AUTOSAR XML (schema 3.1.2)
package /Components/SWC_ExMGslT1
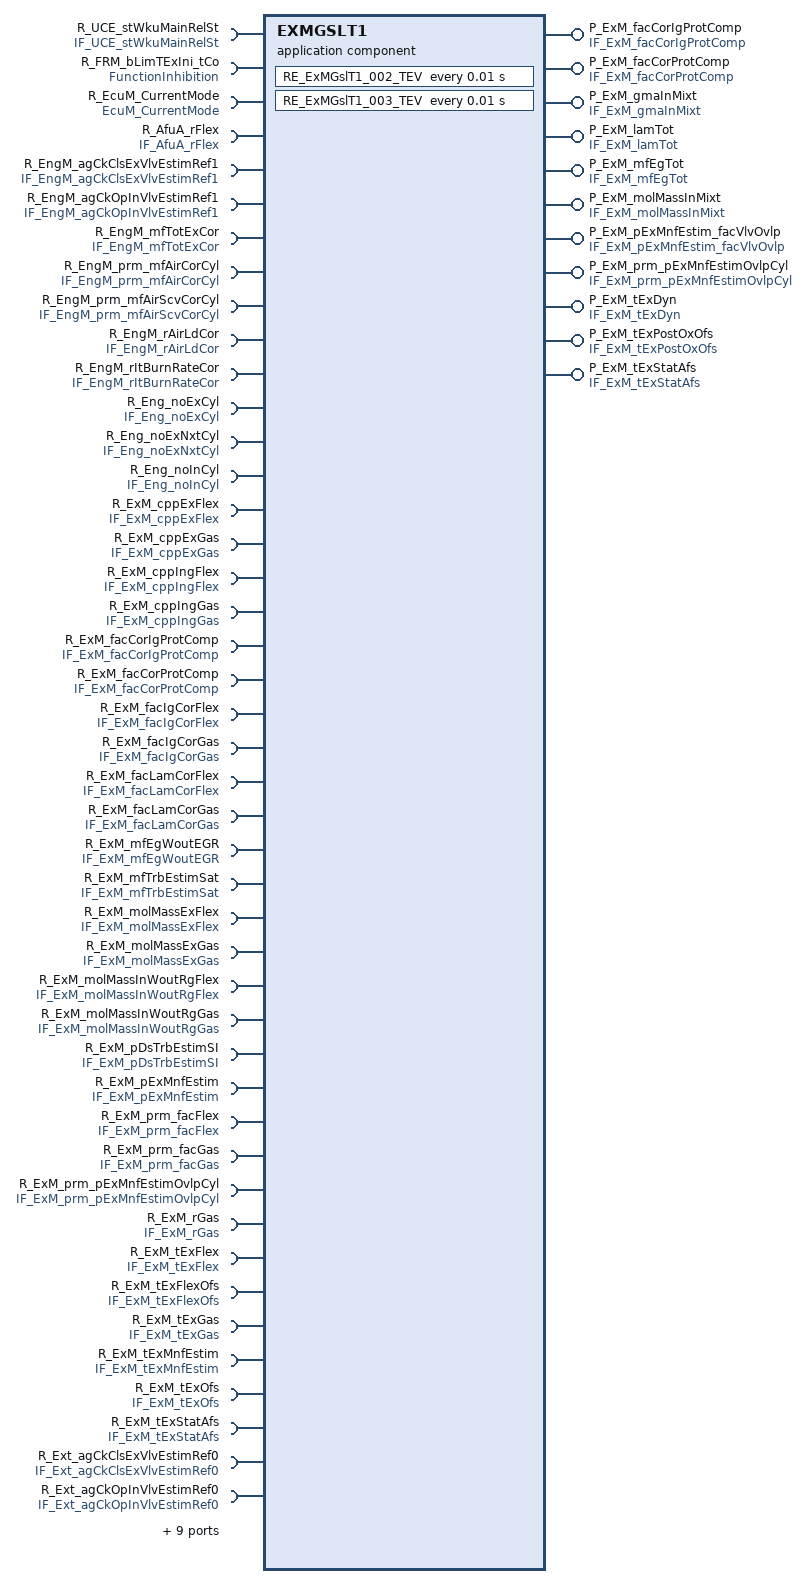
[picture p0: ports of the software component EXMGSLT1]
  application software component type EXMGSLT1  # ExMGslT1
    require port R_UCE_stWkuMainRelSt: required-interface=IF_UCE_stWkuMainRelSt
    require port R_FRM_bLimTExIni_tCo: required-interface=FunctionInhibition
    11 x provide port:
      P_ExM_facCorIgProtComp: unqueued-sender-com-spec{data-element=ExM_facCorIgProtComp, can-invalidate=false, init-value=UInt16InitValue}, provided-interface=IF_ExM_facCorIgProtComp
      P_ExM_facCorProtComp: unqueued-sender-com-spec{data-element=ExM_facCorProtComp, can-invalidate=false, init-value=UInt16InitValue1}, provided-interface=IF_ExM_facCorProtComp
      P_ExM_gmaInMixt: unqueued-sender-com-spec{data-element=ExM_gmaInMixt, can-invalidate=false, init-value=ConstantValue}, provided-interface=IF_ExM_gmaInMixt
      P_ExM_lamTot: unqueued-sender-com-spec{data-element=ExM_lamTot, can-invalidate=false, init-value=UInt32InitValue}, provided-interface=IF_ExM_lamTot
      P_ExM_mfEgTot: unqueued-sender-com-spec{data-element=ExM_mfEgTot, can-invalidate=false, init-value=UInt16InitValue3}, provided-interface=IF_ExM_mfEgTot
      P_ExM_molMassInMixt: unqueued-sender-com-spec{data-element=ExM_molMassInMixt, can-invalidate=false, init-value=ConstantValue5}, provided-interface=IF_ExM_molMassInMixt
      P_ExM_pExMnfEstim_facVlvOvlp: unqueued-sender-com-spec{data-element=ExM_pExMnfEstim_facVlvOvlp, can-invalidate=false, init-value=ConstantValue7}, provided-interface=IF_ExM_pExMnfEstim_facVlvOvlp
      P_ExM_prm_pExMnfEstimOvlpCyl: unqueued-sender-com-spec{data-element=ExM_prm_pExMnfEstimOvlpCyl, can-invalidate=false, init-value=ArrayConstantValue}, provided-interface=IF_ExM_prm_pExMnfEstimOvlpCyl
      P_ExM_tExDyn: unqueued-sender-com-spec{data-element=ExM_tExDyn, can-invalidate=false, init-value=ConstantValue9}, provided-interface=IF_ExM_tExDyn
      P_ExM_tExPostOxOfs: unqueued-sender-com-spec{data-element=ExM_tExPostOxOfs, can-invalidate=false, init-value=UInt16InitValue11}, provided-interface=IF_ExM_tExPostOxOfs
      P_ExM_tExStatAfs: unqueued-sender-com-spec{data-element=ExM_tExStatAfs, can-invalidate=false, init-value=UInt16InitValue13}, provided-interface=IF_ExM_tExStatAfs
    51 x require port:
      R_EcuM_CurrentMode: required-interface=EcuM_CurrentMode
      R_AfuA_rFlex: unqueued-receiver-com-spec{data-element=AfuA_rFlex, init-value=UInt8InitValue, resync-time=0}, required-interface=IF_AfuA_rFlex
      R_EngM_agCkClsExVlvEstimRef1: unqueued-receiver-com-spec{data-element=EngM_agCkClsExVlvEstimRef1, init-value=ConstantValue15, resync-time=0}, required-interface=IF_EngM_agCkClsExVlvEstimRef1
      R_EngM_agCkOpInVlvEstimRef1: unqueued-receiver-com-spec{data-element=EngM_agCkOpInVlvEstimRef1, init-value=ConstantValue17, resync-time=0}, required-interface=IF_EngM_agCkOpInVlvEstimRef1
      R_EngM_mfTotExCor: unqueued-receiver-com-spec{data-element=EngM_mfTotExCor, init-value=ConstantValue19, resync-time=0}, required-interface=IF_EngM_mfTotExCor
      R_EngM_prm_mfAirCorCyl: unqueued-receiver-com-spec{data-element=EngM_prm_mfAirCorCyl, init-value=ArrayConstantValue21, resync-time=0}, required-interface=IF_EngM_prm_mfAirCorCyl
      R_EngM_prm_mfAirScvCorCyl: unqueued-receiver-com-spec{data-element=EngM_prm_mfAirScvCorCyl, init-value=ArrayConstantValue23, resync-time=0}, required-interface=IF_EngM_prm_mfAirScvCorCyl
      R_EngM_rAirLdCor: unqueued-receiver-com-spec{data-element=EngM_rAirLdCor, init-value=ConstantValue25, resync-time=0}, required-interface=IF_EngM_rAirLdCor
      R_EngM_rItBurnRateCor: unqueued-receiver-com-spec{data-element=EngM_rItBurnRateCor, init-value=ConstantValue27, resync-time=0}, required-interface=IF_EngM_rItBurnRateCor
      R_Eng_noExCyl: unqueued-receiver-com-spec{data-element=Eng_noExCyl, init-value=ConstantValue29, resync-time=0}, required-interface=IF_Eng_noExCyl
      R_Eng_noExNxtCyl: unqueued-receiver-com-spec{data-element=Eng_noExNxtCyl, init-value=ConstantValue31, resync-time=0}, required-interface=IF_Eng_noExNxtCyl
      R_Eng_noInCyl: unqueued-receiver-com-spec{data-element=Eng_noInCyl, init-value=ConstantValue33, resync-time=0}, required-interface=IF_Eng_noInCyl
      R_ExM_cppExFlex: unqueued-receiver-com-spec{data-element=ExM_cppExFlex, init-value=UInt16InitValue35, resync-time=0}, required-interface=IF_ExM_cppExFlex
      R_ExM_cppExGas: unqueued-receiver-com-spec{data-element=ExM_cppExGas, init-value=SInt16InitValue, resync-time=0}, required-interface=IF_ExM_cppExGas
      R_ExM_cppIngFlex: unqueued-receiver-com-spec{data-element=ExM_cppIngFlex, init-value=ConstantValue1, resync-time=0}, required-interface=IF_ExM_cppIngFlex
      R_ExM_cppIngGas: unqueued-receiver-com-spec{data-element=ExM_cppIngGas, init-value=SInt16InitValue39, resync-time=0}, required-interface=IF_ExM_cppIngGas
      R_ExM_facCorIgProtComp: unqueued-receiver-com-spec{data-element=ExM_facCorIgProtComp, init-value=UInt16InitValue, resync-time=0}, required-interface=IF_ExM_facCorIgProtComp
      R_ExM_facCorProtComp: unqueued-receiver-com-spec{data-element=ExM_facCorProtComp, init-value=UInt16InitValue41, resync-time=0}, required-interface=IF_ExM_facCorProtComp
      R_ExM_facIgCorFlex: unqueued-receiver-com-spec{data-element=ExM_facIgCorFlex, init-value=UInt16InitValue43, resync-time=0}, required-interface=IF_ExM_facIgCorFlex
      R_ExM_facIgCorGas: unqueued-receiver-com-spec{data-element=ExM_facIgCorGas, init-value=UInt16InitValue45, resync-time=0}, required-interface=IF_ExM_facIgCorGas
      R_ExM_facLamCorFlex: unqueued-receiver-com-spec{data-element=ExM_facLamCorFlex, init-value=UInt16InitValue47, resync-time=0}, required-interface=IF_ExM_facLamCorFlex
      R_ExM_facLamCorGas: unqueued-receiver-com-spec{data-element=ExM_facLamCorGas, init-value=UInt16InitValue49, resync-time=0}, required-interface=IF_ExM_facLamCorGas
      R_ExM_mfEgWoutEGR: unqueued-receiver-com-spec{data-element=ExM_mfEgWoutEGR, init-value=UInt16InitValue51, resync-time=0}, required-interface=IF_ExM_mfEgWoutEGR
      R_ExM_mfTrbEstimSat: unqueued-receiver-com-spec{data-element=ExM_mfTrbEstimSat, init-value=UInt16InitValue53, resync-time=0}, required-interface=IF_ExM_mfTrbEstimSat
      R_ExM_molMassExFlex: unqueued-receiver-com-spec{data-element=ExM_molMassExFlex, init-value=UInt16InitValue55, resync-time=0}, required-interface=IF_ExM_molMassExFlex
      R_ExM_molMassExGas: unqueued-receiver-com-spec{data-element=ExM_molMassExGas, init-value=SInt32InitValue, resync-time=0}, required-interface=IF_ExM_molMassExGas
      R_ExM_molMassInWoutRgFlex: unqueued-receiver-com-spec{data-element=ExM_molMassInWoutRgFlex, init-value=UInt16InitValue57, resync-time=0}, required-interface=IF_ExM_molMassInWoutRgFlex
      R_ExM_molMassInWoutRgGas: unqueued-receiver-com-spec{data-element=ExM_molMassInWoutRgGas, init-value=SInt32InitValue59, resync-time=0}, required-interface=IF_ExM_molMassInWoutRgGas
      R_ExM_pDsTrbEstimSI: unqueued-receiver-com-spec{data-element=ExM_pDsTrbEstimSI, init-value=UInt16InitValue61, resync-time=0}, required-interface=IF_ExM_pDsTrbEstimSI
      R_ExM_pExMnfEstim: unqueued-receiver-com-spec{data-element=ExM_pExMnfEstim, init-value=UInt16InitValue63, resync-time=0}, required-interface=IF_ExM_pExMnfEstim
      R_ExM_prm_facFlex: unqueued-receiver-com-spec{data-element=ExM_prm_facFlex, init-value=rt_Array_UInt16_5InitValue, resync-time=0}, required-interface=IF_ExM_prm_facFlex
      R_ExM_prm_facGas: unqueued-receiver-com-spec{data-element=ExM_prm_facGas, init-value=rt_Array_UInt16_5InitValue65, resync-time=0}, required-interface=IF_ExM_prm_facGas
      R_ExM_prm_pExMnfEstimOvlpCyl: unqueued-receiver-com-spec{data-element=ExM_prm_pExMnfEstimOvlpCyl, init-value=ArrayConstantValue, resync-time=0}, required-interface=IF_ExM_prm_pExMnfEstimOvlpCyl
      R_ExM_rGas: unqueued-receiver-com-spec{data-element=ExM_rGas, init-value=UInt8InitValue67, resync-time=0}, required-interface=IF_ExM_rGas
      R_ExM_tExFlex: unqueued-receiver-com-spec{data-element=ExM_tExFlex, init-value=UInt16InitValue69, resync-time=0}, required-interface=IF_ExM_tExFlex
      R_ExM_tExFlexOfs: unqueued-receiver-com-spec{data-element=ExM_tExFlexOfs, init-value=SInt16InitValue71, resync-time=0}, required-interface=IF_ExM_tExFlexOfs
      R_ExM_tExGas: unqueued-receiver-com-spec{data-element=ExM_tExGas, init-value=SInt32InitValue73, resync-time=0}, required-interface=IF_ExM_tExGas
      R_ExM_tExMnfEstim: unqueued-receiver-com-spec{data-element=ExM_tExMnfEstim, init-value=ConstantValue75, resync-time=0}, required-interface=IF_ExM_tExMnfEstim
      R_ExM_tExOfs: unqueued-receiver-com-spec{data-element=ExM_tExOfs, init-value=SInt16InitValue77, resync-time=0}, required-interface=IF_ExM_tExOfs
      R_ExM_tExStatAfs: unqueued-receiver-com-spec{data-element=ExM_tExStatAfs, init-value=UInt16InitValue79, resync-time=0}, required-interface=IF_ExM_tExStatAfs
      R_Ext_agCkClsExVlvEstimRef0: unqueued-receiver-com-spec{data-element=Ext_agCkClsExVlvEstimRef0, init-value=ConstantValue81, resync-time=0}, required-interface=IF_Ext_agCkClsExVlvEstimRef0
      R_Ext_agCkOpInVlvEstimRef0: unqueued-receiver-com-spec{data-element=Ext_agCkOpInVlvEstimRef0, init-value=ConstantValue83, resync-time=0}, required-interface=IF_Ext_agCkOpInVlvEstimRef0
      R_Ext_nEng: unqueued-receiver-com-spec{data-element=Ext_nEng, init-value=ConstantValue85, resync-time=0}, required-interface=IF_Ext_nEng
      R_Ext_tCoMes: unqueued-receiver-com-spec{data-element=Ext_tCoMes, init-value=ConstantValue87, resync-time=0}, required-interface=IF_Ext_tCoMes
      R_FARSp_rMixtCylSp: unqueued-receiver-com-spec{data-element=FARSp_rMixtCylSp, init-value=ConstantValue89, resync-time=0}, required-interface=IF_FARSp_rMixtCylSp
      R_IgSys_bAcvStructAir: unqueued-receiver-com-spec{data-element=IgSys_bAcvStructAir, init-value=ConstantValue91, resync-time=0}, required-interface=IF_IgSys_bAcvStructAir
      R_IgSys_lamClc: unqueued-receiver-com-spec{data-element=IgSys_lamClc, init-value=ConstantValue93, resync-time=0}, required-interface=IF_IgSys_lamClc
      R_IgSys_rDynIgSpEfc: unqueued-receiver-com-spec{data-element=IgSys_rDynIgSpEfc, init-value=ConstantValue95, resync-time=0}, required-interface=IF_IgSys_rDynIgSpEfc
      R_InThM_tAirUsInVlvEstim: unqueued-receiver-com-spec{data-element=InThM_tAirUsInVlvEstim, init-value=ConstantValue97, resync-time=0}, required-interface=IF_InThM_tAirUsInVlvEstim
      R_InjSys_bTotCutOff: unqueued-receiver-com-spec{data-element=InjSys_bTotCutOff, init-value=ConstantValue99, resync-time=0}, required-interface=IF_InjSys_bTotCutOff
      R_UsThrM_pAirExt: unqueued-receiver-com-spec{data-element=UsThrM_pAirExt, init-value=ConstantValue101, resync-time=0}, required-interface=IF_UsThrM_pAirExt
  59 x constant specification:
    ArrayConstantValue
      value:
        array specification ArrayConstantValue: type=rt_Array_UInt16_6_m2
          6 x integer literal, all with type=DT_ExM_prm_pExMnfEstimOvlpCyl, value=0:
            Const
            Const{1..5}
    ArrayConstantValue21
      value:
        array specification ArrayConstantValue21: type=rt_Array_UInt16_6_m6
          6 x integer literal, all with type=DT_EngM_prm_mfAirCorCyl, value=43:
            Const
            Const{1..5}
    ArrayConstantValue23
      value:
        array specification ArrayConstantValue23: type=rt_Array_UInt16_6_m7
          6 x integer literal, all with type=DT_EngM_prm_mfAirScvCorCyl, value=0:
            Const
            Const{1..5}
    ConstantValue
      value:
        integer literal ConstantValue: type=DT_ExM_gmaInMixt, value=0
    ConstantValue1
      value:
        integer literal ConstantValue1: type=DT_ExM_cppIngFlex, value=2000
    ConstantValue101
      value:
        integer literal ConstantValue101: type=DT_UsThrM_pAirExt, value=0
    ConstantValue15
      value:
        integer literal ConstantValue15: type=DT_EngM_agCkClsExVlvEstimRef1, value=0
    ConstantValue17
      value:
        integer literal ConstantValue17: type=DT_EngM_agCkOpInVlvEstimRef1, value=0
    ConstantValue19
      value:
        integer literal ConstantValue19: type=DT_EngM_mfTotExCor, value=0
    ConstantValue25
      value:
        integer literal ConstantValue25: type=DT_EngM_rAirLdCor, value=0
    ConstantValue27
      value:
        integer literal ConstantValue27: type=DT_EngM_rItBurnRateCor, value=0
    ConstantValue29
      value:
        integer literal ConstantValue29: type=DT_Eng_noExCyl, value=1
    ConstantValue31
      value:
        integer literal ConstantValue31: type=DT_Eng_noExNxtCyl, value=1
    ConstantValue33
      value:
        integer literal ConstantValue33: type=DT_Eng_noInCyl, value=1
    ConstantValue5
      value:
        integer literal ConstantValue5: type=DT_ExM_molMassInMixt, value=0
    ConstantValue7
      value:
        integer literal ConstantValue7: type=DT_ExM_pExMnfEstim_facVlvOvlp, value=0
    ConstantValue75
      value:
        integer literal ConstantValue75: type=DT_ExM_tExMnfEstim, value=4800
    ConstantValue81
      value:
        integer literal ConstantValue81: type=DT_Ext_agCkClsExVlvEstimRef0, value=-1024
    ConstantValue83
      value:
        integer literal ConstantValue83: type=DT_Ext_agCkOpInVlvEstimRef0, value=-1024
    ConstantValue85
      value:
        integer literal ConstantValue85: type=DT_Ext_nEng, value=0
    ConstantValue87
      value:
        integer literal ConstantValue87: type=DT_Ext_tCoMes, value=20
    ConstantValue89
      value:
        integer literal ConstantValue89: type=DT_FARSp_rMixtCylSp, value=4096
    ConstantValue9
      value:
        integer literal ConstantValue9: type=DT_ExM_tExDyn, value=0
    ConstantValue91
      value:
        boolean literal ConstantValue91: type=DT_IgSys_bAcvStructAir, value=false
    ConstantValue93
      value:
        integer literal ConstantValue93: type=DT_IgSys_lamClc, value=0
    ConstantValue95
      value:
        integer literal ConstantValue95: type=DT_IgSys_rDynIgSpEfc, value=0
    ConstantValue97
      value:
        integer literal ConstantValue97: type=DT_InThM_tAirUsInVlvEstim, value=0
    ConstantValue99
      value:
        boolean literal ConstantValue99: type=DT_InjSys_bTotCutOff, value=false
    rt_Array_UInt16_5InitValue
      value:
        array specification rt_Array_UInt16_5InitValue: type=rt_Array_UInt16_5_m0
          5 x integer literal, all with type=DT_ExM_prm_facFlex, value=0:
            UInt16_{1..5}
    rt_Array_UInt16_5InitValue65
      value:
        array specification rt_Array_UInt16_5InitValue65: type=Array_5_UInt16
          5 x integer literal, all with type=DT_ExM_prm_facGas, value=0:
            UInt16_{1..5}
    SInt16InitValue
      value:
        integer literal SInt16InitValue: type=DT_ExM_cppExGas, value=2000
    SInt16InitValue39
      value:
        integer literal SInt16InitValue39: type=DT_ExM_cppIngGas, value=2000
    SInt16InitValue71
      value:
        integer literal SInt16InitValue71: type=DT_ExM_tExFlexOfs, value=-1
    SInt16InitValue77
      value:
        integer literal SInt16InitValue77: type=DT_ExM_tExOfs, value=-1
    SInt32InitValue
      value:
        integer literal SInt32InitValue: type=DT_ExM_molMassExGas, value=3840
    SInt32InitValue59
      value:
        integer literal SInt32InitValue59: type=DT_ExM_molMassInWoutRgGas, value=3712
    SInt32InitValue73
      value:
        integer literal SInt32InitValue73: type=DT_ExM_tExGas, value=0
    UInt16InitValue
      value:
        integer literal UInt16InitValue: type=DT_ExM_facCorIgProtComp, value=16384
    UInt16InitValue1
      value:
        integer literal UInt16InitValue1: type=DT_ExM_facCorProtComp, value=0
    UInt16InitValue11
      value:
        integer literal UInt16InitValue11: type=DT_ExM_tExPostOxOfs, value=0
    UInt16InitValue13
      value:
        integer literal UInt16InitValue13: type=DT_ExM_tExStatAfs, value=4800
    UInt16InitValue3
      value:
        integer literal UInt16InitValue3: type=DT_ExM_mfEgTot, value=0
    UInt16InitValue35
      value:
        integer literal UInt16InitValue35: type=DT_ExM_cppExFlex, value=2000
    UInt16InitValue41
      value:
        integer literal UInt16InitValue41: type=DT_ExM_facCorProtComp, value=0
    UInt16InitValue43
      value:
        integer literal UInt16InitValue43: type=DT_ExM_facIgCorFlex, value=16384
    UInt16InitValue45
      value:
        integer literal UInt16InitValue45: type=DT_ExM_facIgCorGas, value=49151
    UInt16InitValue47
      value:
        integer literal UInt16InitValue47: type=DT_ExM_facLamCorFlex, value=16384
    UInt16InitValue49
      value:
        integer literal UInt16InitValue49: type=DT_ExM_facLamCorGas, value=49151
    UInt16InitValue51
      value:
        integer literal UInt16InitValue51: type=DT_ExM_mfEgWoutEGR, value=0
    UInt16InitValue53
      value:
        integer literal UInt16InitValue53: type=DT_ExM_mfTrbEstimSat, value=0
    UInt16InitValue55
      value:
        integer literal UInt16InitValue55: type=DT_ExM_molMassExFlex, value=3840
    UInt16InitValue57
      value:
        integer literal UInt16InitValue57: type=DT_ExM_molMassInWoutRgFlex, value=3712
    UInt16InitValue61
      value:
        integer literal UInt16InitValue61: type=DT_ExM_pDsTrbEstimSI, value=0
    UInt16InitValue63
      value:
        integer literal UInt16InitValue63: type=DT_ExM_pExMnfEstim, value=0
    UInt16InitValue69
      value:
        integer literal UInt16InitValue69: type=DT_ExM_tExFlex, value=24864
    UInt16InitValue79
      value:
        integer literal UInt16InitValue79: type=DT_ExM_tExStatAfs, value=4800
    UInt32InitValue
      value:
        integer literal UInt32InitValue: type=DT_ExM_lamTot, value=8192
    UInt8InitValue
      value:
        integer literal UInt8InitValue: type=DT_AfuA_rFlex, value=0
    UInt8InitValue67
      value:
        integer literal UInt8InitValue67: type=DT_ExM_rGas, value=0
  internal behavior IB_ExMGslT1: component=EXMGSLT1
    timing event EV_ExMGslT1_002_TEV: mode-dependency=dependent-on-mode=[R_UCE_stWkuMainRelSt.RCD_stWkuMainRelSt.PreMainWakeUp, R_UCE_stWkuMainRelSt.RCD_stWkuMainRelSt.PostMainWakeUp, R_UCE_stWkuMainRelSt.RCD_stWkuMainRelSt.Invalid], start-on-event=RE_ExMGslT1_002_TEV, period=0.01
    timing event EV_ExMGslT1_003_TEV: mode-dependency=dependent-on-mode=[R_UCE_stWkuMainRelSt.RCD_stWkuMainRelSt.PreMainWakeUp, R_UCE_stWkuMainRelSt.RCD_stWkuMainRelSt.PostMainWakeUp, R_UCE_stWkuMainRelSt.RCD_stWkuMainRelSt.Invalid], start-on-event=RE_ExMGslT1_003_TEV, period=0.01
    mode switch event EV_ExMGslT1_005_MSE: start-on-event=RE_ExMGslT1_005_MSE, activation=ENTRY, mode=R_EcuM_CurrentMode.currentMode.RUN
    mode switch event EV_ExMGslT1_004_MSE: start-on-event=RE_ExMGslT1_004_MSE, activation=ENTRY, mode=R_EcuM_CurrentMode.currentMode.RUN
    4 x runnable:
      RE_ExMGslT1_004_MSE
        data receive point dr_Ext_tCoMes: data-element=R_Ext_tCoMes.Ext_tCoMes
        9 x data send point:
          ds_ExM_mfEgTot: data-element=P_ExM_mfEgTot.ExM_mfEgTot
          ds_ExM_facCorIgProtComp: data-element=P_ExM_facCorIgProtComp.ExM_facCorIgProtComp
          ds_ExM_tExPostOxOfs: data-element=P_ExM_tExPostOxOfs.ExM_tExPostOxOfs
          ds_ExM_tExDyn: data-element=P_ExM_tExDyn.ExM_tExDyn
          ds_ExM_gmaInMixt: data-element=P_ExM_gmaInMixt.ExM_gmaInMixt
          ds_ExM_lamTot: data-element=P_ExM_lamTot.ExM_lamTot
          ds_ExM_tExStatAfs: data-element=P_ExM_tExStatAfs.ExM_tExStatAfs
          ds_ExM_facCorProtComp: data-element=P_ExM_facCorProtComp.ExM_facCorProtComp
          ds_ExM_molMassInMixt: data-element=P_ExM_molMassInMixt.ExM_molMassInMixt
      RE_ExMGslT1_002_TEV
        38 x data receive point:
          dr_ExM_tExStatAfs: data-element=R_ExM_tExStatAfs.ExM_tExStatAfs
          dr_EngM_prm_mfAirCorCyl: data-element=R_EngM_prm_mfAirCorCyl.EngM_prm_mfAirCorCyl
          dr_FARSp_rMixtCylSp: data-element=R_FARSp_rMixtCylSp.FARSp_rMixtCylSp
          dr_ExM_molMassInWoutRgGas: data-element=R_ExM_molMassInWoutRgGas.ExM_molMassInWoutRgGas
          dr_ExM_tExFlex: data-element=R_ExM_tExFlex.ExM_tExFlex
          dr_InThM_tAirUsInVlvEstim: data-element=R_InThM_tAirUsInVlvEstim.InThM_tAirUsInVlvEstim
          dr_IgSys_bAcvStructAir: data-element=R_IgSys_bAcvStructAir.IgSys_bAcvStructAir
          dr_EngM_prm_mfAirScvCorCyl: data-element=R_EngM_prm_mfAirScvCorCyl.EngM_prm_mfAirScvCorCyl
          dr_Ext_agCkOpInVlvEstimRef0: data-element=R_Ext_agCkOpInVlvEstimRef0.Ext_agCkOpInVlvEstimRef0
          dr_ExM_prm_facGas: data-element=R_ExM_prm_facGas.ExM_prm_facGas
          dr_EngM_mfTotExCor: data-element=R_EngM_mfTotExCor.EngM_mfTotExCor
          dr_ExM_facIgCorFlex: data-element=R_ExM_facIgCorFlex.ExM_facIgCorFlex
          dr_ExM_cppIngGas: data-element=R_ExM_cppIngGas.ExM_cppIngGas
          dr_ExM_molMassExGas: data-element=R_ExM_molMassExGas.ExM_molMassExGas
          dr_ExM_tExOfs: data-element=R_ExM_tExOfs.ExM_tExOfs
          dr_ExM_prm_facFlex: data-element=R_ExM_prm_facFlex.ExM_prm_facFlex
          dr_IgSys_rDynIgSpEfc: data-element=R_IgSys_rDynIgSpEfc.IgSys_rDynIgSpEfc
          dr_EngM_rItBurnRateCor: data-element=R_EngM_rItBurnRateCor.EngM_rItBurnRateCor
          dr_Ext_tCoMes: data-element=R_Ext_tCoMes.Ext_tCoMes
          dr_ExM_tExGas: data-element=R_ExM_tExGas.ExM_tExGas
          dr_EngM_rAirLdCor: data-element=R_EngM_rAirLdCor.EngM_rAirLdCor
          dr_ExM_cppIngFlex: data-element=R_ExM_cppIngFlex.ExM_cppIngFlex
          dr_ExM_cppExFlex: data-element=R_ExM_cppExFlex.ExM_cppExFlex
          dr_ExM_molMassExFlex: data-element=R_ExM_molMassExFlex.ExM_molMassExFlex
          dr_ExM_facIgCorGas: data-element=R_ExM_facIgCorGas.ExM_facIgCorGas
          dr_Eng_noInCyl: data-element=R_Eng_noInCyl.Eng_noInCyl
          dr_InjSys_bTotCutOff: data-element=R_InjSys_bTotCutOff.InjSys_bTotCutOff
          dr_ExM_facCorIgProtComp: data-element=R_ExM_facCorIgProtComp.ExM_facCorIgProtComp
          dr_ExM_molMassInWoutRgFlex: data-element=R_ExM_molMassInWoutRgFlex.ExM_molMassInWoutRgFlex
          dr_ExM_facLamCorFlex: data-element=R_ExM_facLamCorFlex.ExM_facLamCorFlex
          dr_Ext_agCkClsExVlvEstimRef0: data-element=R_Ext_agCkClsExVlvEstimRef0.Ext_agCkClsExVlvEstimRef0
          dr_ExM_tExFlexOfs: data-element=R_ExM_tExFlexOfs.ExM_tExFlexOfs
          dr_ExM_cppExGas: data-element=R_ExM_cppExGas.ExM_cppExGas
          dr_Ext_nEng: data-element=R_Ext_nEng.Ext_nEng
          dr_ExM_facCorProtComp: data-element=R_ExM_facCorProtComp.ExM_facCorProtComp
          dr_IgSys_lamClc: data-element=R_IgSys_lamClc.IgSys_lamClc
          dr_ExM_facLamCorGas: data-element=R_ExM_facLamCorGas.ExM_facLamCorGas
          dr_Eng_noExCyl: data-element=R_Eng_noExCyl.Eng_noExCyl
        9 x data send point:
          ds_ExM_mfEgTot: data-element=P_ExM_mfEgTot.ExM_mfEgTot
          ds_ExM_gmaInMixt: data-element=P_ExM_gmaInMixt.ExM_gmaInMixt
          ds_ExM_facCorProtComp: data-element=P_ExM_facCorProtComp.ExM_facCorProtComp
          ds_ExM_tExPostOxOfs: data-element=P_ExM_tExPostOxOfs.ExM_tExPostOxOfs
          ds_ExM_tExDyn: data-element=P_ExM_tExDyn.ExM_tExDyn
          ds_ExM_tExStatAfs: data-element=P_ExM_tExStatAfs.ExM_tExStatAfs
          ds_ExM_facCorIgProtComp: data-element=P_ExM_facCorIgProtComp.ExM_facCorIgProtComp
          ds_ExM_molMassInMixt: data-element=P_ExM_molMassInMixt.ExM_molMassInMixt
          ds_ExM_lamTot: data-element=P_ExM_lamTot.ExM_lamTot
        sync call ssp_FRM_bLimTExIni_tCo: operation=R_FRM_bLimTExIni_tCo.GetFunctionPermission
      RE_ExMGslT1_005_MSE
        data send point ds_ExM_prm_pExMnfEstimOvlpCyl: data-element=P_ExM_prm_pExMnfEstimOvlpCyl.ExM_prm_pExMnfEstimOvlpCyl
        data send point ds_ExM_pExMnfEstim_facVlvOvlp: data-element=P_ExM_pExMnfEstim_facVlvOvlp.ExM_pExMnfEstim_facVlvOvlp
      RE_ExMGslT1_003_TEV
        14 x data receive point:
          dr_Eng_noExCyl: data-element=R_Eng_noExCyl.Eng_noExCyl
          dr_UsThrM_pAirExt: data-element=R_UsThrM_pAirExt.UsThrM_pAirExt
          dr_ExM_rGas: data-element=R_ExM_rGas.ExM_rGas
          dr_EngM_agCkOpInVlvEstimRef1: data-element=R_EngM_agCkOpInVlvEstimRef1.EngM_agCkOpInVlvEstimRef1
          dr_ExM_mfEgWoutEGR: data-element=R_ExM_mfEgWoutEGR.ExM_mfEgWoutEGR
          dr_AfuA_rFlex: data-element=R_AfuA_rFlex.AfuA_rFlex
          dr_ExM_pExMnfEstim: data-element=R_ExM_pExMnfEstim.ExM_pExMnfEstim
          dr_ExM_mfTrbEstimSat: data-element=R_ExM_mfTrbEstimSat.ExM_mfTrbEstimSat
          dr_Ext_nEng: data-element=R_Ext_nEng.Ext_nEng
          dr_Eng_noExNxtCyl: data-element=R_Eng_noExNxtCyl.Eng_noExNxtCyl
          dr_ExM_tExMnfEstim: data-element=R_ExM_tExMnfEstim.ExM_tExMnfEstim
          DRP_R_ExM_prm_pExMnfEstimOvlpCyl_ExM_prm_pExMnfEstimOvlpCyl: data-element=R_ExM_prm_pExMnfEstimOvlpCyl.ExM_prm_pExMnfEstimOvlpCyl
          dr_EngM_agCkClsExVlvEstimRef1: data-element=R_EngM_agCkClsExVlvEstimRef1.EngM_agCkClsExVlvEstimRef1
          dr_ExM_pDsTrbEstimSI: data-element=R_ExM_pDsTrbEstimSI.ExM_pDsTrbEstimSI
        data send point ds_ExM_prm_pExMnfEstimOvlpCyl: data-element=P_ExM_prm_pExMnfEstimOvlpCyl.ExM_prm_pExMnfEstimOvlpCyl
        data send point ds_ExM_pExMnfEstim_facVlvOvlp: data-element=P_ExM_pExMnfEstim_facVlvOvlp.ExM_pExMnfEstim_facVlvOvlp
  swc implementation Imp_ExMGslT1: code-generator=Real-Time Workshop Embedded Coder 5.5 (R2010a) 25-Jan-2010, programming-language=C, behavior=IB_ExMGslT1
    code-descriptors:
      code CodeDescriptor: type=SRC
        9 x xfile:
          ExMGslT1_Version_h: url=ExMGslT1_Version.h
          ExMGslT1_types_h: url=ExMGslT1_types.h
          ExMGslT1_import_h: url=ExMGslT1_import.h
          ExMGslT1_h: url=ExMGslT1.h
          ExMGslT1_Version_c: url=ExMGslT1_Version.c
          ExMGslT1_c: url=ExMGslT1.c
          ExMGslT1_MemMap_h: url=ExMGslT1_MemMap.h
          ExMGslT1_Def_c: url=ExMGslT1_Def.c
          ExMGslT1_private_h: url=ExMGslT1_private.h
